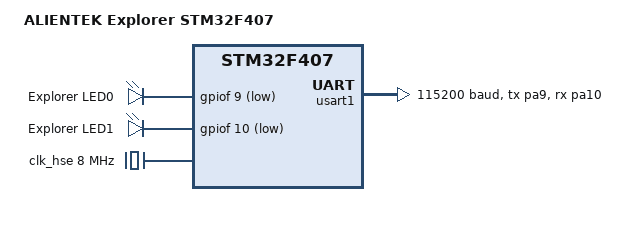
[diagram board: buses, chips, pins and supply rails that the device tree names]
/dts-v1/;

#include <st/f4/stm32f407Xe.dtsi>
#include <st/f4/stm32f407z(e-g)tx-pinctrl.dtsi>

/ {
	model = "ALIENTEK Explorer STM32F407";
	compatible = "alientek,stm32f407-explorer";

	chosen {
		zephyr,console = &usart1;
		zephyr,shell-uart = &usart1;
		zephyr,sram = &sram0;
		zephyr,flash = &flash0;
		zephyr,dtcm = &ccm0;
	};

	leds {
		compatible = "gpio-leds";

		led0: led_0 {
			gpios = <&gpiof 9 GPIO_ACTIVE_LOW>;
			label = "Explorer LED0";
		};

		led1: led_1 {
			gpios = <&gpiof 10 GPIO_ACTIVE_LOW>;
			label = "Explorer LED1";
		};
	};

	aliases {
		led0 = &led0;
		led1 = &led1;
	};
};

&clk_hse {
	clock-frequency = <DT_FREQ_M(8)>;
	status = "okay";
};

&pll {
	div-m = <8>;
	mul-n = <336>;
	div-p = <2>;
	div-q = <7>;
	clocks = <&clk_hse>;
	status = "okay";
};

&rcc {
	clocks = <&pll>;
	clock-frequency = <DT_FREQ_M(168)>;
	ahb-prescaler = <1>;
	apb1-prescaler = <4>;
	apb2-prescaler = <2>;
};

&usart1 {
	pinctrl-0 = <&usart1_tx_pa9 &usart1_rx_pa10>;
	pinctrl-names = "default";
	current-speed = <115200>;
	status = "okay";
};

&gpiof {
	status = "okay";
};
